# LPC804 register map
Vendor: nxp.com; File version: 1.0
CPU: CM0PLUS r0p0, little endian, no MPU, no FPU, VTOR, 2 interrupt priority bits
Registers are 32-bit, read-write, reset 0x0 unless marked. A register's access mark holds for its fields unless they carry their own. Offsets are from the block's base; [hi:lo] are bit positions; lines under a group give offsets from that group; {n}, {i} and the like mark numbered series; 'fields as' and 'values as' point back to an identical list.

## PMU — LPC80X PMU
Base 0x40020000
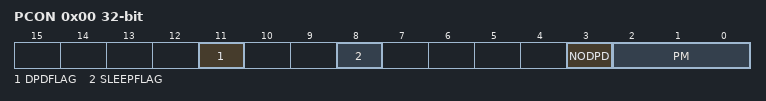
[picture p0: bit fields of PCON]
0x00 PCON — Power control register
  [11] DPDFLAG — Deep power-down flag
    0=NOT_DEEP_POWER_DOWN (Not Deep power-down. Read: Deep power-down mode not entered. Write: No effect.); 1=DEEP_POWER_DOWN (Deep power-down. Read: Deep power-down mode entered. Write: Clear the Deep power-down flag.)
  [8] SLEEPFLAG — Sleep mode flag
    0=ACTIVE_MODE (Active mode. Read: No power-down mode entered. Part is in Active mode. Write: No effect.); 1=LOW_POWER_MODE (Low power mode. Read: Sleep, Deep-sleep or Power-down mode entered. Write: Writing a 1 clears the SLEEPFLAG bit to 0.)
  [3] NODPD — A 1 in this bit prevents entry to Deep power-down mode when 0x3 is written to the PM field above, the SLEEPDEEP bit is set, and a WFI is executed. This bit is cleared only by power-on reset, so writing a one to this bit locks the part in a mode in which Deep power-down mode is blocked.
  [2:0] PM — Power mode
    0=DEFAULT (Default. The part is in active or sleep mode.); 1=DEEP_SLEEP_MODE (Deep-sleep mode. ARM WFI will enter Deep-sleep mode.); 2=POWER_DOWN_MODE (Power-down mode. ARM WFI will enter Power-down mode.); 3=DEEP_POWER_DOWN_MODE (Deep power-down mode. ARM WFI will enter Deep-power down mode (ARM Cortex-M0+ core powered-down).)
{0x4+4i} GPREG[{i}] (i=0..4) — General purpose register N
  [31:0] GPDATA — Data retained during Deep power-down mode.
0x20 WUSRCREG — Pin wake-up source register
  [7:0] WUSRCREG — Pin wake-up source
0x24 WUENAREG — Pin wake-up enable register
  [7:0] WUENAREG — Pin wake-up enable

## ACOMP — LPC80X analog comparator
Base 0x40024000
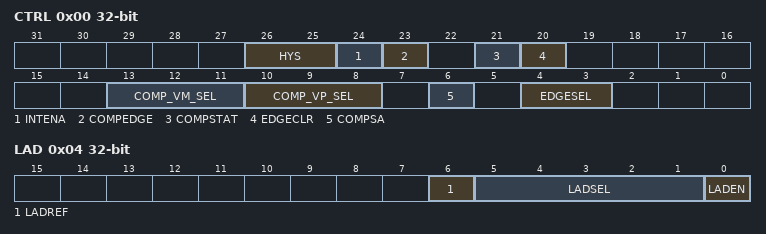
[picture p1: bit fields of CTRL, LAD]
0x00 CTRL (reset mask 0x6C03F58) — Comparator control register
  [26:25] HYS — Controls the hysteresis of the comparator. When the comparator is outputting a certain state, this is the difference between the selected signals, in the opposite direction from the state being output, that will switch the output.
    0=None (the output will switch as the voltages cross); 1=5 mv; 2=10 mv; 3=20 mv
  [24] INTENA — Must be set to generate interrupts.
  [23] COMPEDGE — Comparator edge-detect status.
  [21] COMPSTAT — Comparator status. This bit reflects the state of the comparator output.
  [20] EDGECLR — Interrupt clear bit. To clear the COMPEDGE bit and thus negate the interrupt request, toggle the EDGECLR bit by first writing a 1 and then a 0.
  [13:11] COMP_VM_SEL — Selects negative voltage input
    0=VOLTAGE_LADDER_OUTPUT; {v}=ACMP_I{v} (v=1..5); 6=BAND_GAP (Band gap. Internal reference voltage.); 7=DACOUT0 (DAC0 output)
  [10:8] COMP_VP_SEL — Selects positive voltage input
    values as COMP_VM_SEL
  [6] COMPSA — Comparator output control
    0=Comparator output is used directly; 1=Comparator output is synchronized to the bus clock for output to other modules
  [4:3] EDGESEL — This field controls which edges on the comparator output set the COMPEDGE bit (bit 23 below):
    0=FALLING_EDGES; 1=RISING_EDGES; 2=BOTH_EDGES0; 3=BOTH_EDGES1
0x04 LAD — Voltage ladder register
  [6] LADREF — Selects the reference voltage Vref for the voltage ladder.
    0=Supply pin VDD; 1=VDDCMP pin
  [5:1] LADSEL — Voltage ladder value. The reference voltage Vref depends on the LADREF bit below. 00000 = VSS 00001 = 1 x Vref/31 00010 = 2 x Vref/31 ... 11111 = Vref
  [0] LADEN — Voltage ladder enable

## PLU — LPC80X Programmable Logic Unit (PLU)
Base 0x40028000
{0x0+0x20*i} LUT[{i}] (i=0..25) group
  {0x0+4j} LUT_INP_MUX{j} (j=0..4) — LUT0 input 0 MUX
    [5:0] LUTn_INPx — Selects the input source to be connected to LUT0 input0. For each LUT, the slot associated with the output from LUTn itself is tied low.
      {v}=plu_inputs{v} (The PLU primary inputs {v}.) (v=0..5); {v}=lut_outputs{v-6} (The output of LUT{v-6}.) (v=6..31); {v}=state{v-32} (v=32..35)
{0x800+4i} LUT_TRUTH[{i}] (i=0..25) — Specifies the Truth Table contents for LUT0
  [31:0] LUTn_TRUTH — Specifies the Truth Table contents for LUT0..
0x900 OUTPUTS — Provides the current state of the 8 designated PLU Outputs.
  [7:0] OUTPUT_STATE ro — Provides the current state of the 8 designated PLU Outputs..
{0xC00+4i} OUTPUT_MUX[{i}] (i=0..7) — Selects the source to be connected to PLU Output 0
  [4:0] OUTPUTn — Selects the source to be connected to PLU Output 0.
    {v}=plu_output{v} (The PLU output {v}.) (v=0..25); {v}=state{v-26} (v=26..29)
